# D1H register map
Vendor: Allwinner; File version: 1.0
Registers are 32-bit, read-write, reset 0x0 unless marked. A register's access mark holds for its fields unless they carry their own. Offsets are from the block's base; [hi:lo] are bit positions; lines under a group give offsets from that group; {n}, {i} and the like mark numbered series; 'fields as' and 'values as' point back to an identical list.

## CSIC — CMOS Sensor Interface Controller
Base 0x05800000
0x00 csic_ccu group
  0x00 ccu_clk_mode — CCU Clock Mode Register
    [31] ccu_clk_gating_disable
      0=EFFECT (CCU Clock Gating Registers(0x0004~0x0010) effect); 1=NOT_EFFECT (CCU Clock Gating Registers(0x0004~0x0010) not effect)
  0x04 ccu_parser_clk_en — CCU Parser Clock Enable Register
    [0] mcsi_parser0_clk_enable
      0=DISABLE (CSI Parser0 clock disable); 1=ENABLE (CSI Parser0 clock enable)
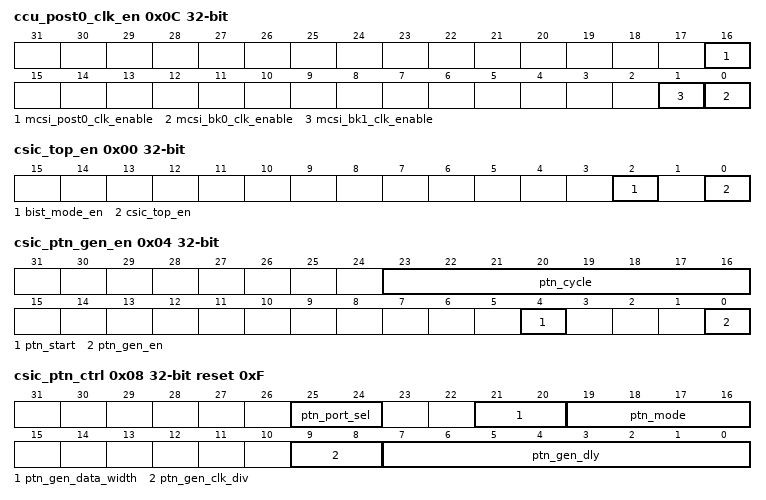
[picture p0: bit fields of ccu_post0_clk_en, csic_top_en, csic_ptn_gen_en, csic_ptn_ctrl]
  0x0C ccu_post0_clk_en — CCU Post0 Clock Enable Register
    [16] mcsi_post0_clk_enable
      0=DISABLE (POST0 clock disable); 1=ENABLE (POST0 clock enable)
    [n] mcsi_bk{n}_clk_enable (n=0..1)
      0=DISABLE (BK[i] clock disable); 1=ENABLE (BK[i] clock enable,when MCSI_POST0_CLK_ENABLE is 1)
0x800 csic_top group
  0x00 csic_top_en — CSIC TOP Enable Register
    [2] bist_mode_en
      0=C_LOSED; 1=EN (EN BIST TEST)
    [0] csic_top_en
      0=RESET_DISABLE (Reset and disable the CSIC module); 1=ENABLE (Enable the CSIC module)
  0x04 csic_ptn_gen_en — CSIC Pattern Generation Enable Register
    [23:16] ptn_cycle — Pattern generating cycle counter. . The pattern in dram will be generated in cycles of PTN_CYCLE+1.
    [4] ptn_start — CSIC Pattern Generating Start . Software write this bit to "1" to start pattern generating from DRAM. When finished, the hardware will clear this bit to "0" automatically. Generating cycles depends on PTN_CYCLE.
      0=F_INISH; 1=S_TART
    [0] ptn_gen_en — Pattern Generation Enable
  0x08 csic_ptn_ctrl reset 0xF — CSIC Pattern Control Register
    [25:24] ptn_port_sel — Pattern Generator output port selection
      2=NSCIC0
    [21:20] ptn_gen_data_width
      0=8BIT; 1=10BIT; 2=12BIT
    [19:16] ptn_mode — Pattern mode selection
      4=NCSIC_YUV_8BIT; 5=NCSIC_YUV_16BIT; 9=BT656_8BIT; 10=BT656_16BIT; 13=BAYER_12BIT; 14=UYVY422_12BIT; 15=UYVY420_12BIT
    [9:8] ptn_gen_clk_div — Packet generator clock divider
    [7:0] ptn_gen_dly — Clocks delayed before pattern generating start.
  0x20 csic_ptn_len — CSIC Pattern Generation Length Register
    [31:0] ptn_len — The pattern length in byte when generating pattern.
  0x24 csic_ptn_addr — CSIC Pattern Generation Address Register
    [31:0] ptn_addr — The pattern DRAM address when generating pattern.
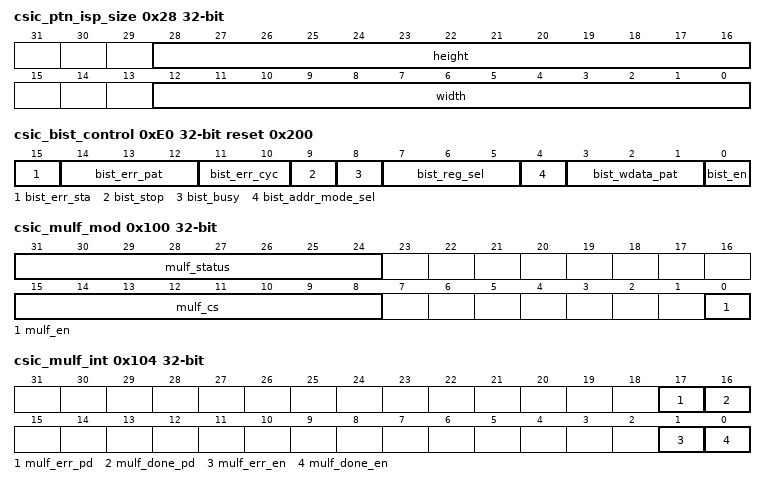
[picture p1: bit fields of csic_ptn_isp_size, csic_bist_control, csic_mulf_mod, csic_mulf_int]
  0x28 csic_ptn_isp_size — CSIC Pattern ISP Size Register
    [28:16] height — Height Vertical size, only valid for ISP mode pattern generation.
    [12:0] width — Width Horizontal size, only valid for ISP mode pattern generation.
  {0xA0+4j} csic_dma{j}_input_sel (j=0..1) — CSIC DMA[i] Input Select Register
    [3:0] input_sel — Input selection for DMA[i]
      {v}=ISP0_CH{v} (v=0..3)
  0xDC csic_bist_cs
    [2:0] bist_cs
      0=SET_BK0 (Set when BK0 memory bist); 1=SET_BK1 (Set when BK1 memory bist)
  0xE0 csic_bist_control reset 0x200
    [15] bist_err_sta ro — BIST error status
      0=NO_EFFECT; 1=ERROR
    [14:12] bist_err_pat ro — BIST error pattern
    [11:10] bist_err_cyc ro — BIST error cycle
    [9] bist_stop ro
      0=RUNNING; 1=STOP
    [8] bist_busy ro
      0=IDLE; 1=BUSY
    [7:5] bist_reg_sel — BIST register select
    [4] bist_addr_mode_sel — BIST address mode select
    [3:1] bist_wdata_pat — BIST write data pattern
      0=0X00000000; 1=0X55555555; 2=0X33333333; 3=0X0F0F0F0F; 4=0X00FF00FF; 5=0X0000FFFF
    [0] bist_en — BIST enable . A positive will trigger the BIST to start.
  0xE4 csic_bist_start_addr — CSIC BIST Start Address Register
    [31:0] bist_start_addr — BIST start address, 32-bit aligned
  0xE8 csic_bist_end_addr — CSIC BIST End Address Register
    [31:0] bist_end_addr — BIST end address, 32-bit aligned
  0xEC csic_bist_data_mask
    [31:0] bist_data_mask
      0=UNMASK; 1=MASK
  0xF0 csic_mbus_req_max reset 0xF
    [4:0] mcsi_mem_req_max — Maximum of request commands for the master granted in MCSI_MEM arbiter is N+1.
  0x100 csic_mulf_mod — CSIC Multi-Frame Mode Register
    [31:24] mulf_status ro, [15:8] mulf_cs, [0] mulf_en
  0x104 csic_mulf_int — CSIC Multi-Frame Interrupt Register
    [17] mulf_err_pd write-1-clears, [16] mulf_done_pd write-1-clears, [1] mulf_err_en, [0] mulf_done_en
0x1000 csic_parser0 group
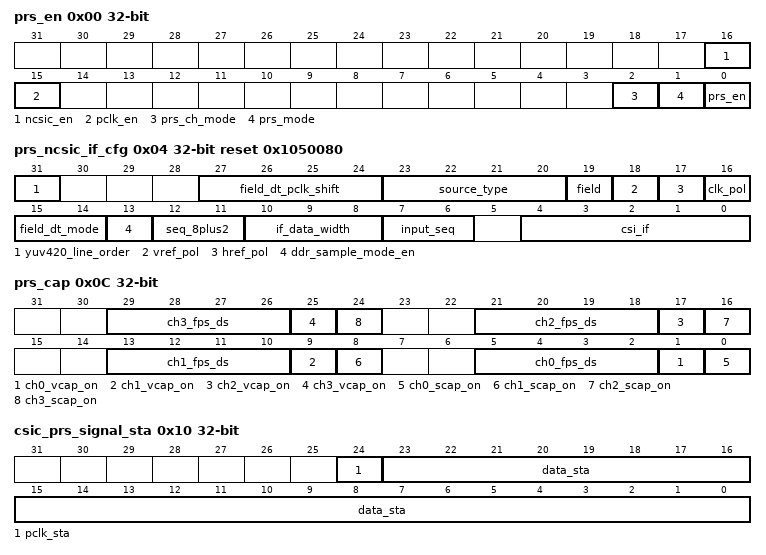
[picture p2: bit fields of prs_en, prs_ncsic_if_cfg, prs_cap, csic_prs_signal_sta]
  0x00 prs_en — Parser Enable Register
    [16] ncsic_en
      0=RESET_DISABLE (Reset and disable the NCSIC module); 1=ENABLE (Enable the NCSIC module)
    [15] pclk_en
      0=G_ATE (Gate pclk input); 1=ENABLE (Enable pclk input)
    [2] prs_ch_mode
      0=CORRESPONDING (Parser output channel 0-3 corresponding from input channel 0-3); 1=ALL_FROM_0 (Parser output channel 0-3 all from input channel 0 (MIPI SEHDR))
    [1] prs_mode
      1=MCSI
    [0] prs_en
      0=RESET_DISABLE (Reset and disable the parser module); 1=ENABLE (Enable the parser module)
  0x04 prs_ncsic_if_cfg reset 0x1050080 — Parser NCSIC Interface Configuration Register
    [31] yuv420_line_order
      0=Y_YC_Y_YC (YUV420 input in Y_YC_Y_YC line order); 1=YC_Y_YC_Y (YUV420 input in YC_Y_YC_Y line order)
    [27:24] field_dt_pclk_shift — Only for vsync detected field mode, the odd field permitted pclk shift = 4 * FIELD_DT_PCLK_SHIFT
    [23:20] source_type — Bit 20-23 corresponding to the SRC_TYPEs for channel 0-3
      0=P_ROGRESSED; 1=INTERLACED
    [19] field — Field polarity (For YUV HV timing) / Field sequence (For BT656 timing)
      0=NEGATIVE_NORMAL_SEQ; 1=POSITIVE_INVERSE_SEQ
    [18] vref_pol — Vref polarity . This register is not applied to CCIR656 interface
      0=NEGATIVE; 1=POSITIVE
    [17] href_pol — Href polarity . This register is not applied to CCIR656 interface
      0=NEGATIVE; 1=POSITIVE
    [16] clk_pol — Data clock type
      0=RISING (active in rising edge); 1=FALLING (active in falling edge)
    [15:14] field_dt_mode — only valid when CSI_IF is YUB and source type is interlaced
      0=BY_FIELD_VSYNC (by both field and vsync); 1=BY_FIELD; 2=BY_VSYNC
    [13] ddr_sample_mode_en
      0=DISABLE; 1=ENABLE
    [12:11] seq_8plus2 — When select IF_DATA_WIDTH to be 8+2bit, odd/even pixel byte at CSI-D[11:4] will be rearranged to D[11:2]+2'b0 at the actual CSI data bus according to these sequences
      0=PD98_D70 (6'bx + D[9:8], D[7:0]); 1=D92_PD10 (D[9:2], 6'bx + D[1:0]); 2=D70_D98P (D[7:0], D[9:8] + 6'bx); 3=D70_PD98 (D[7:0], 6'bx + D[9:8])
    [10:8] if_data_width
      0=8BIT (8 bit data bus); 1=10BIT (10 bit data bus); 2=12BIT (12 bit data bus); 3=8P2BIT (8 + 2 bit data bus); 4=2X8BIT (2 * 8 bit data bus)
    [7:6] input_seq — Input data sequence, only valid for YUV422 and YUV420 input format
      0=YUYV; 1=YVYU; 2=UYVY; 3=VYUY
    [4:0] csi_if
      0=RAW_YUV420_YUYV422 (RAW or YUV420/YUYV422 (each cycle one component input)); 4=BT656_1CH (BT656 1 channel); 12=BT656_2CH (BT656 2 channel (All data interleaved in one data bus)); 14=BT656_4CH (BT656 4 channel (All data interleaved in one data bus))
  0x0C prs_cap — Parser Capture Register
    [8n+5:8n+2] ch{n}_fps_ds (n=0..3) — Fps down sample
      0=NO_DOWN_SAMPLE; {v}=1_{v+1} (1/{v+1} fps, only receives the first frame every {v+1} frames) (v=2..8); {v}=1/{v+1} fps, only receives the first frame every {v+1} frames (v=9..15)
    [8n+1] ch{n}_vcap_on (n=0..3) — Video capture control: Capture the video image data stream on channel [i].
      0=DISABLE (Disable video capture . If video capture is in progress, the CSI stops capturing image data at the end of the current frame, and all of the current frame data is written to output FIFO.); 1=ENABLE (Enable video capture . The CSI starts capturing image data at the start of the next frame.)
    [8n] ch{n}_scap_on (n=0..3) ro read-clears — Still capture control: Capture a single still image frame on channel [i].
      0=DISABLE (Disable still capture); 1=ENABLE (Enable still capture . The CSI module starts capturing image data at the start of the next frame. The CSI module captures only one frame of image data. This bit is self cleared and always reads as a 0.)
  0x10 csic_prs_signal_sta — CSIC Parser Signal Status Register
    [24] pclk_sta ro — Indicates the pclk status
      0=LOW; 1=HIGH
    [23:0] data_sta ro — Indicates the Dn status (n=0-23), MSB for D23, LSB for D0
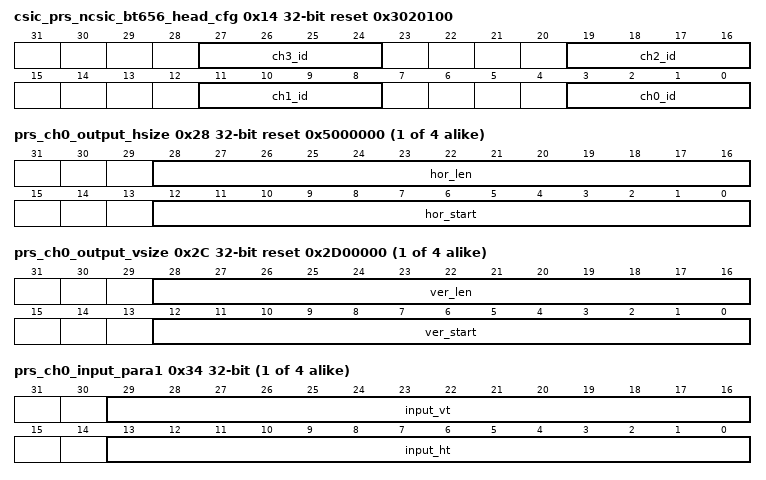
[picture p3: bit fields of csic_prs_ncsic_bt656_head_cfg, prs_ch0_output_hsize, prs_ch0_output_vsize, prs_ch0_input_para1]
  0x14 csic_prs_ncsic_bt656_head_cfg reset 0x3020100 (reset mask 0xF0F0F0F) — CSIC Parser NCSIC BT656 Header Configuration Register
    [8n+3:8n] ch{n}_id (n=0..3) — The low 4-bit of BT656 header for channel [i] . Only valid in BT656 multi-channel mode
  {0x24+0x100*j} prs_ch{j}_infmt (j=0..3) reset 0x3 — Parser Channel[i] Input Format Register
    [3:0] input_fmt — input data format
      0=RAW (RAW stream); 3=YUV422; 4=YUV420
  {0x28+0x100*j} prs_ch{j}_output_hsize (j=0..3) reset 0x5000000 — Parser Channel[i] Output Horizontal Size Register
    [28:16] hor_len — Horizontal pixel unit length. Valid pixel of a line.
    [12:0] hor_start — Horizontal pixel unit start. Pixel is valid from this pixel.
  {0x2C+0x100*j} prs_ch{j}_output_vsize (j=0..3) reset 0x2D00000 — Parser Channel[i] Output Vertical Size Register
    [28:16] ver_len — Valid line number of a frame.
    [12:0] ver_start — Vertical line start. Data is valid from this line.
  {0x30+0x100*j} prs_ch{j}_input_para0 (j=0..3) ro — Parser Channel[i] Input Parameter0 Register
    [0] input_src_type
      0=PROGRESS; 1=INTERLACE
  {0x34+0x100*j} prs_ch{j}_input_para1 (j=0..3) ro — Parser Channel[i] Input Parameter1 Register
    [29:16] input_vt — INPUT_VT = INPUT_VB + INPUT_Y
    [13:0] input_ht — INPUT_HT = INPUT_HB + INPUT_X
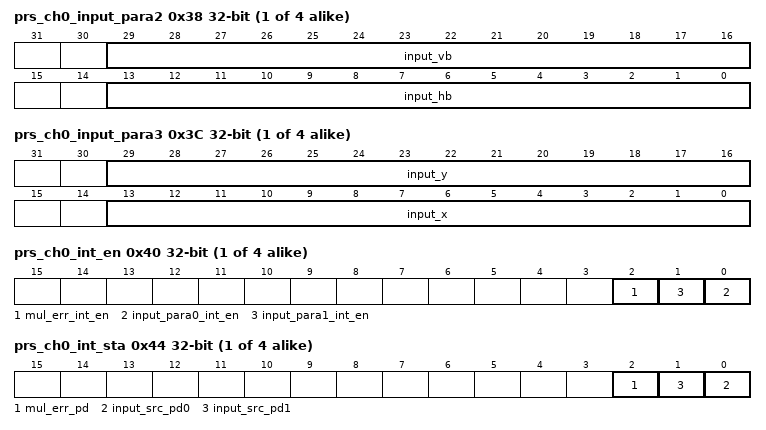
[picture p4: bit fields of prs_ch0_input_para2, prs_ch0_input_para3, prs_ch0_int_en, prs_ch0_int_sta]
  {0x38+0x100*j} prs_ch{j}_input_para2 (j=0..3) ro — Parser Channel[i] Input Parameter2 Register
    [29:16] input_vb, [13:0] input_hb
  {0x3C+0x100*j} prs_ch{j}_input_para3 (j=0..3) ro — Parser Channel[i] Input Parameter3 Register
    [29:16] input_y, [13:0] input_x
  {0x40+0x100*j} prs_ch{j}_int_en (j=0..3) — Parser Channel[i] Interrupt Enable Register
    [2] mul_err_int_en — Multi-channel writing error . Indicates error has been detected for writing data to a wrong channel
      0=DISABLE; 1=ENABLE
    [n] input_para{n}_int_en (n=0..1)
      0=DISABLE; 1=ENABLE
  {0x44+0x100*j} prs_ch{j}_int_sta (j=0..3) — Parser Channel[i] Interrupt Status Register
    [2] mul_err_pd write-1-clears — Multi-channel writing error pending
      0=NO_PENDING; 1=PENDING
    [n] input_src_pd{n} (n=0..1) write-1-clears
      0=NO_PENDING; 1=PENDING
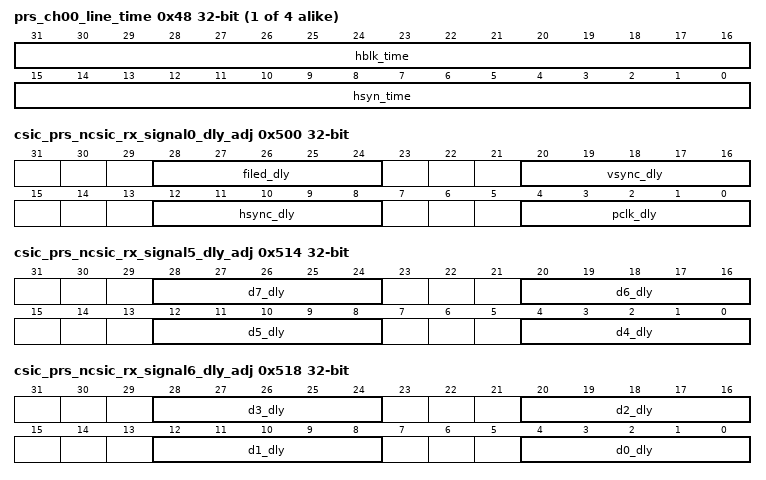
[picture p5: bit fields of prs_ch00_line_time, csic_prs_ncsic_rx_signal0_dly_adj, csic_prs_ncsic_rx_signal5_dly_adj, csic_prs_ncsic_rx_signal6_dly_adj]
  {0x48+0x100*j} prs_ch{j}0_line_time (j=0..3) ro — Parser Channel[i] Line Time Register
    [31:16] hblk_time — Time of H Blanking when vsync is valid . The unit is csi_top_clk cycle
    [15:0] hsyn_time — Time of H SYNC when vsync is valid . The unit is csi_top_clk cycle
  0x500 csic_prs_ncsic_rx_signal0_dly_adj — CSIC Parser NCSIC RX Signal0 Delay Adjust Register
    [28:24] filed_dly — Filed_dly 32 Step for adjust, 1 step = 0.2 ns
    [20:16] vsync_dly — Vsync_dly 32 Step for adjust, 1 step = 0.2 ns
    [12:8] hsync_dly — Hsync_dly 32 Step for adjust, 1 step = 0.2 ns
    [4:0] pclk_dly — Pclk_dly 32 Step for adjust, 1 step = 0.2 ns
  0x514 csic_prs_ncsic_rx_signal5_dly_adj — CSIC Parser NCSIC RX Signal5 Delay Adjust Register
    [8n-28:8n-32] d{n}_dly (n=4..7) — D{n}_dly 32 Step for adjust, 1 step = 0.2 ns
  0x518 csic_prs_ncsic_rx_signal6_dly_adj — CSIC Parser NCSIC RX Signal6 Delay Adjust Register
    [8n+4:8n] d{n}_dly (n=0..3) — D{n}_dly 32 Step for adjust, 1 step = 0.2 ns
{0x9000+0x200*i} csic_dma{i} (i=0..1) group
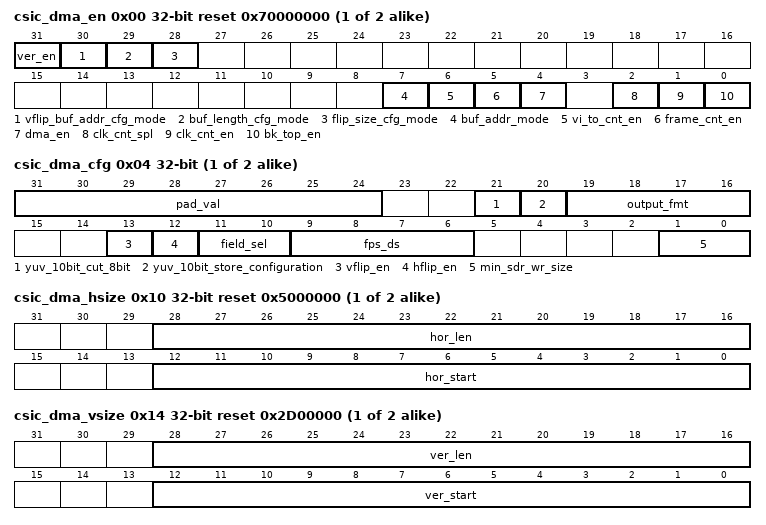
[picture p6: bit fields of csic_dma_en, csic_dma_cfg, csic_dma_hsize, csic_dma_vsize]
  0x00 csic_dma_en reset 0x70000000 — CSIC DMA Enable Register
    [31] ver_en
    [30] vflip_buf_addr_cfg_mode — Vflip buffer address set by software or calculated by hardware
      0=H_ARDWARE; 1=S_OFTWARE
    [29] buf_length_cfg_mode — Buffer length set by software or calculated by hardware
      0=H_ARDWARE; 1=S_OFTWARE
    [28] flip_size_cfg_mode — FLIP SIZE set by software or calculated by hardware
      0=H_ARDWARE; 1=S_OFTWARE
    [7] buf_addr_mode
      0=R_EGISTER (Buffer Address Register Mode); 1=FIFO (Buffer Address FIFO Mode)
    [6] vi_to_cnt_en — Enable Video Input Timeout counter, add 1 when there is no effective video input in a 12M clock, clear to 0 when detecting effective video input.
      0=DISABLE; 1=ENABLE
    [5] frame_cnt_en — When BK_TOP_EN is enabled, setting 1 to this bit indicates the Frame counter starts to add.
      0=DISABLE; 1=ENABLE
    [4] dma_en — When BK_TOP_EN is enabled, setting 1 to this bit indicates the module works in DMA mode.
      0=DISABLE; 1=ENABLE
    [2] clk_cnt_spl — Sampling time for clk counter per frame
      0=FRAME_DONE (Sampling clock counter every frame done); 1=VSYNC (Sampling clock counter every vsync)
    [1] clk_cnt_en — clk count per frame enable
      0=DISABLE; 1=ENABLE
    [0] bk_top_en
      0=DISABLE; 1=ENABLE
  0x04 csic_dma_cfg — CSIC DMA Configuration Register
    [31:24] pad_val — Padding value when OUTPUT_FMT is prgb888 . 0x00-0xff
    [21] yuv_10bit_cut_8bit — 10-bit input cut to 8-bit
      0=DISABLE; 1=ENABLE
    [20] yuv_10bit_store_configuration — 10-bit store configuration
      0=LOW (YUV 10-bit stored in low 10-bit of a 16-bit word); 1=HIGH (YUV 10-bit stored in high 10-bit of a 16-bit word)
    [19:16] output_fmt — Output data format . When the input format is set to RAW stream . 0000: field-raw-8 . 0001: field-raw-10 . 0010: field-raw-12 . 0011: reserved . 0100: field-rgb565 . 0101: field-rgb888 . 0110: field-prgb888 . 0111: reserved . 1000: frame-raw-8 . 1001: frame-raw-10 . 1010: frame-raw-12 . 1011: reserved . 1100: frame-rgb565 . 1101: frame-rgb888 . 1110: frame-prgb888 . 1111: reserved . When the input format is set to YUV422 . 0000: field planar YCbCr 422 . 0001: field planar YCbCr 420 . 0010: frame planar YCbCr 420 . 0011: frame planar YCbCr 422 . 0100: field planar YCbCr 422 UV combined (UV sequence) . 0101: field planar YCbCr 420 UV combined (UV sequence) . 0110: frame planar YCbCr 420 UV combined (UV sequence) . 0111: frame planar YCbCr 422 UV combined (UV sequence) . 1000: filed planar YCbCr 422 UV combined (VU sequence) . 1001: field planar YCbCr 420 UV combined (VU sequence) . 1010: frame planar YCbCr 420 UV combined (VU sequence) . 1011: frame planar YCbCr 422 UV combined (VU sequence) . 1100: reserved . 1101: field YCbCr 400 . 1110: reserved . 1111: frame YCbCr 400 . When the input format is set to YUV420 . 0000: reserved . 0001: field planar YCbCr 420 . 0010: frame planar YCbCr 420 . 0011: reserved . 0100: reserved . 0101: field planar YCbCr 420 UV combined (UV sequence) . 0110: frame planar YCbCr 420 UV combined (UV sequence) 0111~1000: reserved . 1001: field planar YCbCr 420 UV combined (VU sequence) . 1010: frame planar YCbCr 420 UV combined (VU sequence) 1011~1100: reserved . 1101: field YCbCr 400 . 1110: reserved . 1111: frame YCbCr 400
    [13] vflip_en — Vertical flip enable . When enabled, the received data will be arranged in vertical flip.
      0=DISABLE; 1=ENABLE
    [12] hflip_en — Horizontal flip enable . When enabled, the received data will be arranged in horizontal flip.
      0=DISABLE; 1=ENABLE
    [11:10] field_sel — Field selection
      0=FIELD_0 (Capturing with field 0); 1=FIELD_1 (Capturing with field 1); 2=EITHER_FIELD (Capturing with either field)
    [9:6] fps_ds — Fps down sample
      values as csic_parser0.prs_cap.ch0_fps_ds
    [1:0] min_sdr_wr_size — Minimum size of SDRAM block write
      0=256 bytes (if hflip is enabled, always select 256 bytes); 1=512 bytes; 2=1K (1K bytes); 3=2K (2K bytes)
  0x10 csic_dma_hsize reset 0x5000000 — CSIC DMA Horizontal Size Register
    [28:16] hor_len — When BK_TOP_EN is enabled, DMA_EN is enabled, these bits indicate Horizontal pixel unit length. Valid pixel of a line in DMA mode.
    [12:0] hor_start — Horizontal pixel unit start. . Pixel is valid from this pixel.
  0x14 csic_dma_vsize reset 0x2D00000 — CSIC DMA Vertical Size Register
    [28:16] ver_len — When BK_TOP_EN is enabled, DMA_EN is enabled, these bits indicate Valid line number of a frame in DMA mode.
    [12:0] ver_start — Vertical line start . Data is valid from this line.
  0x20 csic_dma_f0_bufa — CSIC DMA FIFO 0 Output Buffer-A Address Register
    [31:0] f0_bufa — When BK_TOP_EN is enabled, FBC_EN is enabled, DMA_EN is disabled, these bits indicate output address of overhead data in FBC mode. . When BK_TOP_EN is enabled, FBC_EN is disabled, DMA_EN is enabled, LBC_EN is disabled, these bits indicate FIFO 0 output buffer-A address in DMA mode. . When BK_TOP_EN is enabled, FBC_EN is disabled, DMA_EN is enabled, LBC_EN is enabled, these bits indicate the output buffer address in LBC mode.
  {0x24+8j} csic_dma_f{j}_bufa_result (j=0..2) — CSIC DMA FIFO {j} Output Buffer-A Address Result Register
    [31:0] f{j}_bufa_result ro — Indicate the final F{j}_BUFA address used for DMA or FBC after software configuration or hardware calculation from Buffer-A address register or buffer address fifo. Only used for debug.
  0x28 csic_dma_f1_bufa — CSIC DMA FIFO 1 Output Buffer-A Address Register
    [31:0] f1_bufa — When BK_TOP_EN is enabled, FBC_EN is enabled, DMA_EN is disabled, these bits indicate the output address of compressed data in FBC mode. . When BK_TOP_EN is enabled, FBC_EN is disabled, DMA_EN is enabled, these bits indicate the FIFO 1 output buffer-A address in DMA mode.
  0x30 csic_dma_f2_bufa — CSIC DMA FIFO 2 Output Buffer-A Address Register
    [31:0] f2_bufa — FIFO 2 output buffer-A address.
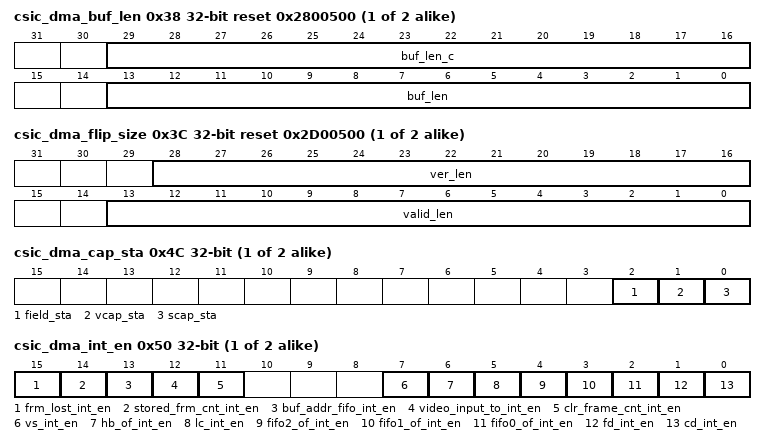
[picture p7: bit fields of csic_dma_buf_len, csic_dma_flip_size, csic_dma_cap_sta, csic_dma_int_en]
  0x38 csic_dma_buf_len reset 0x2800500 — CSIC DMA Buffer Length Register
    [29:16] buf_len_c — DMA_MODE: Buffer length of chroma C in a line. Unit is byte. . LBC_MODE: Buffer length Stride of luminance Y in ONLY Y line. Unit is byte. . Only Readable when BUF_LENGTH_CFG_MODE is set 0.
    [13:0] buf_len — DMA_MODE:Buffer length of luminance Y in a line. Unit is byte. . LBC_MODE: Buffer length Stride of luminance Y and chroma C in YC line. Unit is byte. . Only Readable when BUF_LENGTH_CFG_MODE is set 0.
  0x3C csic_dma_flip_size reset 0x2D00500
    [28:16] ver_len — Vertical line number when in VFLIP mode. Unit is line. . Only Readable when FLIP_SIZE_CFG_MODE is set to 0.
    [13:0] valid_len — Valid components of a line when in HFLIP mode. Unit is pixel component. . Only Readable when FLIP_SIZE_CFG_MODE is set to 0.
  0x40 csic_dma_vi_to_th0 — CSIC DMA Video Input Timeout Threshold0 Register
    [31:0] vi_to_th0 — Video Input Timeout Threshold0 . Set VIDEO_INPUT_TO_INT_PD when VI Counter reaches TH0 after VI_TO_CNT_EN is set, the Time Unit is a 12M clock period.
  0x44 csic_dma_vi_to_th1 — CSIC DMA Video Input Timeout Threshold1 Register
    [31:0] vi_to_th1 — Video Input Timeout Threshold1 . Set VIDEO_INPUT_TO_INT_PD when VI Counter reaches TH1 after getting the first frame has been input, the Time Unit is a 12M clock period.
  0x48 csic_dma_vi_to_cnt_val — CSIC DMA Video Input Timeout Counter Value Register
    [31:0] vi_to_cnt_val ro — Video Input Timeout Counter Value . Indicate the current value of Video Input Timeout Counter
  0x4C csic_dma_cap_sta — CSIC DMA Capture Status Register
    [2] field_sta ro — The status of the received field
      0=F_IELD_0; 1=F_IELD_1
    [1] vcap_sta ro — Video capture in progress . Indicates the CSI is capturing video image data (multiple frames). The bit is set at the start of the first frame after enabling video capture. When software disables video capture, it clears itself after the last pixel of the current frame is captured.
    [0] scap_sta ro — Still capture in progress . Indicates the CSI is capturing still image data (single frame). The bit is set at the start of the first frame after enabling still frame capture. It clears itself after the last pixel of the first frame is captured. . For CCIR656 interface, if the output format is frame planar YCbCr 420 mode, the frame end means the field2 end, the other frame end means filed end.
  0x50 csic_dma_int_en — CSIC DMA Interrupt Enable Register
    [15] frm_lost_int_en — Set an INT when frame starts with empty Buffer Address FIFO, only use in BUF Address FIFO MODE.
    [14] stored_frm_cnt_int_en — Set an INT when the value of CSIC_DMA_STORED_FRM_CNT reaches CSIC_DMA_STORED_FRM_THRESHOLD, only use in BUF Address FIFO MODE.
    [13] buf_addr_fifo_int_en — Set an INT when content in BUF Address FIFO less than CSIC_DMA_BUFA_FIFO_THRESHOLD, only use in BUF Address FIFO MODE.
    [12] video_input_to_int_en — Set an INT when no video input exceeds the setting threshold time
    [11] clr_frame_cnt_int_en — Set a INT when clear Frame cnt.
    [7] vs_int_en — vsync flag . The bit is set when vsync come. And at this time load the buffer address for the coming frame. So after this irq come, changing the buffer address could only effect next frame
    [6] hb_of_int_en — Hblank FIFO overflow The bit is set when 3 FIFOs still overflow after the hblank.
    [5] lc_int_en — Line counter flag The bit is set when the specific line has been written to dram every frame. The line number is set in the line counter register.
    [4] fifo2_of_int_en — FIFO 2 overflow . The bit is set when the FIFO 2 became overflow.
    [3] fifo1_of_int_en — FIFO 1 overflow . The bit is set when the FIFO 1 became overflow.
    [2] fifo0_of_int_en — FIFO 0 overflow . The bit is set when the FIFO 0 became overflow.
    [1] fd_int_en — Frame done . Indicates the CSI has finished capturing an image frame. Applies to video capture mode. The bit is set after each completed frame capturing data is written to buffer as long as video capture remains enabled.
    [0] cd_int_en — Capture done . Indicates the CSI has completed capturing the image data. For still capture, the bit is set when one frame data has been written to buffer. For video capture, the bit is set when the last frame has been written to buffer after video capture has been disabled. For CCIR656 interface, if the output format is frame planar YCbCr 420 mode, the frame end means the field2 end, the other frame end means field end.
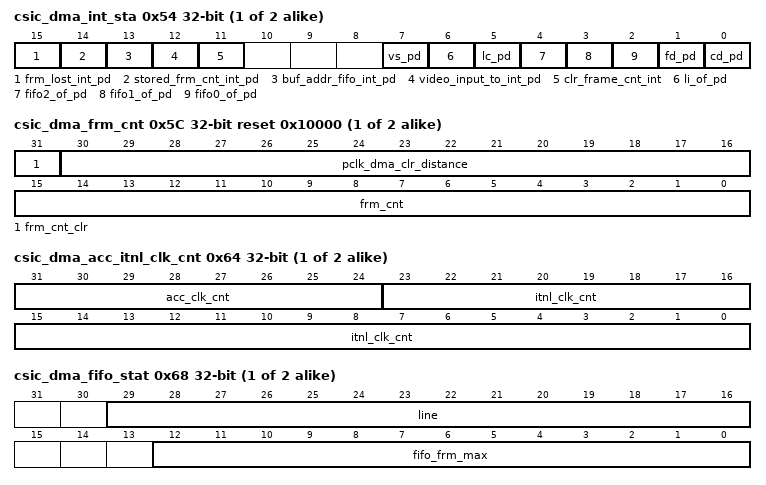
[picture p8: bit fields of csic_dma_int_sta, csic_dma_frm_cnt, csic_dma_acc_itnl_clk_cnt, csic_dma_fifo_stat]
  0x54 csic_dma_int_sta — CSIC DMA Interrupt Status Register
    [15] frm_lost_int_pd write-1-clears — Set an INT when frame starts with empty Buffer Address FIFO, only use in BUF Address FIFO MODE.
    [14] stored_frm_cnt_int_pd write-1-clears — Set an INT when the value of CSIC_DMA_STORED_FRM_CNT reaches CSIC_DMA_STORED_FRM_THRESHOLD, only use in BUF Address FIFO MODE.
    [13] buf_addr_fifo_int_pd write-1-clears — Set an INT when content in BUF Address FIFO less than CSIC_DMA_BUFA_FIFO_THRESHOLD, only use in BUF Address FIFO MODE.
    [12] video_input_to_int_pd write-1-clears — Set an INT Pending when no video input exceeds the setting threshold time.
    [11] clr_frame_cnt_int write-1-clears — Set a INT when clear Frame cnt.
    [7] vs_pd write-1-clears — vsync flag
    [6] li_of_pd write-1-clears — Line information FIFO (16 lines) overflow
    [5] lc_pd write-1-clears — Line counter flag
    [4] fifo2_of_pd write-1-clears — FIFO 2 overflow
    [3] fifo1_of_pd write-1-clears — FIFO 1 overflow
    [2] fifo0_of_pd write-1-clears — FIFO 0 overflow
    [1] fd_pd write-1-clears — Frame done
    [0] cd_pd write-1-clears — Capture done
  0x58 csic_dma_line_cnt — CSIC DMA LINE Counter Register
    [12:0] line_cnt_num — The LINE_CNT_NUM value is set by user,when internal line counter reach the set value, the LC_PD will be set.
  0x5C csic_dma_frm_cnt reset 0x10000 — CSIC DMA Frame Counter Register
    [31] frm_cnt_clr write-1-clears — When the bit set to 1, Frame cnt is cleared to 0.
    [30:16] pclk_dma_clr_distance — Frame cnt clear cycle . N*T_{SYNC}
    [15:0] frm_cnt ro — Counter value of frame. When frame done comes, the internal counter value add 1, and when the reg full, it is cleared to 0 . When parser sent a sync signal, it is cleared to 0.
  0x60 csic_dma_frm_clk_cnt — CSIC DMA Frame Clock Counter Register
    [23:0] frm_clk_cnt ro — Counter value between every frame. For instant hardware frame rate statics. . The internal counter is added by one every 12 MHz clock cycle. When frame done or vsync comes, the internal counter value is sampled to FRM_CLK_CNT, and cleared to 0.
  0x64 csic_dma_acc_itnl_clk_cnt — CSIC DMA Accumulated And Internal Clock Counter Register
    [31:24] acc_clk_cnt write-clears — The accumulated value of FRM_CLK_CNT for software frame rate statics. Every interrupt of frame is done, the software checks this accumulated value and clears it to 0. If the ACC_CLK_CNT is larger than 1, the software has lost frame. . When frame done or vsync comes, ACC_CLK_CNT = ACC_CLK_CNT + 1, and cleared to 0 when writing this register.
    [23:0] itnl_clk_cnt ro — The instant value of internal frame clock counter. . When frame done interrupt comes, the software can query this counter for judging whether it is the time for updating the double buffer address registers.
  0x68 csic_dma_fifo_stat — CSIC DMA FIFO Statistic Register
    [29:16] line ro — Line Index Indicates the line index in current vsync.
    [12:0] fifo_frm_max ro — Indicates the maximum depth of FIFO being occupied for whole frame. Update at every vsync or framedone.
  0x6C csic_dma_fifo_thrs reset 0x400 — CSIC DMA FIFO Threshold Register
    [11:0] fifo_thrs — When FIFO occupied memory exceed the threshold, dram frequency can not change.
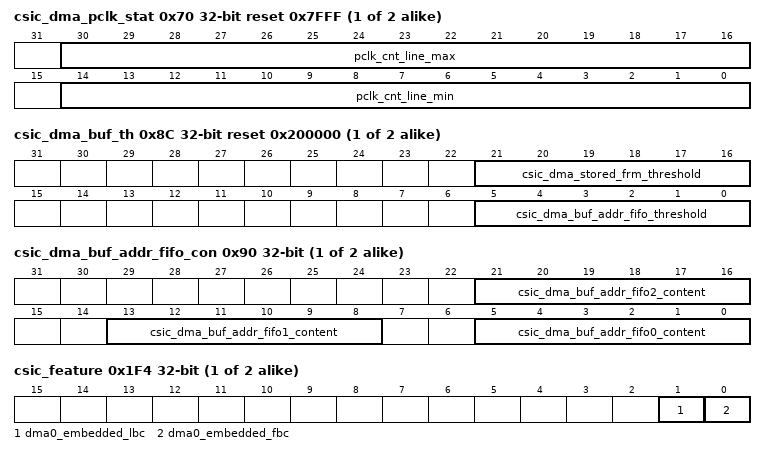
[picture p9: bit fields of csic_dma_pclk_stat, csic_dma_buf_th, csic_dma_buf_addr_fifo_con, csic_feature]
  0x70 csic_dma_pclk_stat reset 0x7FFF — CSIC DMA PCLK Statistic Register
    [30:16] pclk_cnt_line_max ro — Indicates maximum pixel clock counter value for each line. Update at every vsync or framedone.
    [14:0] pclk_cnt_line_min ro — Indicates minimum pixel clock counter value for each line. Update at every vsync or framedone.
  {0x80+4j} csic_dma_buf_addr_fifo{j}_entry (j=0..2) — CSIC DMA BUF Address FIFO[i] Entry Register
    [31:0] csic_dma_buf_addr_fifo_entry — FIFO Entry of Buffer Address FIFO[i] for input frames to be stored, only used in Buffer Addr FIFO Mode
  0x8C csic_dma_buf_th reset 0x200000 — CSIC DMA BUF Threshold Register
    [21:16] csic_dma_stored_frm_threshold — when stored frame counter value reaches the threshold , counter is cleared to 0 , only used in Buffer Addr FIFO Mode.
    [5:0] csic_dma_buf_addr_fifo_threshold — when content in Buffer Address FIFO less than the threshold, an interrupt is set, only used in Buffer Addr FIFO Mode.
  0x90 csic_dma_buf_addr_fifo_con — CSIC DMA BUF Address FIFO Content Register
    [8n+5:8n] csic_dma_buf_addr_fifo{n}_content (n=0..2) ro — FIFO Content of address buffered in Buffer Address FIFO[i], only used in Buffer Addr FIFO Mode.
  0x94 csic_dma_stored_frm_cnt — CSIC DMA Stored Frame Counter Register
    [7:0] csic_dma_stored_frm_cnt ro — Indicates value of stored frames counter. When the counter value reaches CSIC_DMA_STORED_FRM_THRESHOLD, the counter is cleared to 0. Only used in Buffer Addr FIFO Mode.
  0x1F4 csic_feature — CSIC DMA Feature List Register
    [1] dma0_embedded_lbc ro
      0=NO_E_MBEDDED (No Embedded LBC); 1=E_MBEDDED (Embedded LBC)
    [0] dma0_embedded_fbc ro
      0=NO_E_MBEDDED (No Embedded DMA); 1=E_MBEDDED (Embedded FBC)
